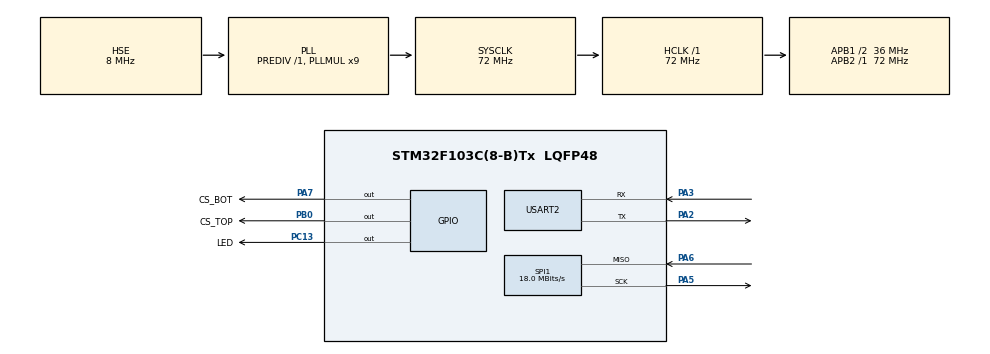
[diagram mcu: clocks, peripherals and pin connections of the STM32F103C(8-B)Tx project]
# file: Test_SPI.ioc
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Dma.Request0=SPI1_RX
Dma.SPI1_RX.0.Direction=DMA_PERIPH_TO_MEMORY
Dma.SPI1_RX.0.Instance=DMA1_Channel2
Dma.SPI1_RX.0.MemDataAlignment=DMA_MDATAALIGN_BYTE
Dma.SPI1_RX.0.MemInc=DMA_MINC_ENABLE
Dma.SPI1_RX.0.Mode=DMA_CIRCULAR
Dma.SPI1_RX.0.PeriphDataAlignment=DMA_PDATAALIGN_BYTE
Dma.SPI1_RX.0.PeriphInc=DMA_PINC_DISABLE
Dma.SPI1_RX.0.Priority=DMA_PRIORITY_LOW
Mcu.Family=STM32F1
Mcu.Name=STM32F103C(8-B)Tx
Mcu.Package=LQFP48
NVIC.DMA1_Channel2_IRQn=true\:0\:0\:false\:false\:true\:false\:true\:true
NVIC.PriorityGroup=NVIC_PRIORITYGROUP_4
NVIC.USART2_IRQn=true\:0\:0\:false\:false\:true\:true\:true\:true
PA13.Mode=Serial_Wire
PA13.Signal=SYS_JTMS-SWDIO
PA14.Mode=Serial_Wire
PA14.Signal=SYS_JTCK-SWCLK
PA2.Mode=Asynchronous
PA2.Signal=USART2_TX
PA3.Mode=Asynchronous
PA3.Signal=USART2_RX
PA5.Mode=RX_Only_Simplex_Unidirect_Master
PA5.Signal=SPI1_SCK
PA6.Mode=RX_Only_Simplex_Unidirect_Master
PA6.Signal=SPI1_MISO
PA7.GPIO_Label=CS_BOT
PA7.PinState=GPIO_PIN_SET
PA7.Signal=GPIO_Output
PB0.GPIO_Label=CS_TOP
PB0.PinState=GPIO_PIN_SET
PB0.Signal=GPIO_Output
PC13-TAMPER-RTC.GPIO_Label=LED
PC13-TAMPER-RTC.Signal=GPIO_Output
PD0-OSC_IN.Mode=HSE-External-Oscillator
PD0-OSC_IN.Signal=RCC_OSC_IN
PD1-OSC_OUT.Mode=HSE-External-Oscillator
PD1-OSC_OUT.Signal=RCC_OSC_OUT
ProjectManager.HeapSize=0x200
ProjectManager.StackSize=0x400
ProjectManager.TargetToolchain=STM32CubeIDE
RCC.AHBFreq_Value=72000000
RCC.APB1CLKDivider=RCC_HCLK_DIV2
RCC.APB1Freq_Value=36000000
RCC.APB1TimFreq_Value=72000000
RCC.APB2Freq_Value=72000000
RCC.APB2TimFreq_Value=72000000
RCC.HCLKFreq_Value=72000000
RCC.PLLMUL=RCC_PLL_MUL9
RCC.PLLSourceVirtual=RCC_PLLSOURCE_HSE
RCC.SYSCLKFreq_VALUE=72000000
RCC.SYSCLKSource=RCC_SYSCLKSOURCE_PLLCLK
RCC.USBFreq_Value=72000000
SPI1.BaudRatePrescaler=SPI_BAUDRATEPRESCALER_4
SPI1.CalculateBaudRate=18.0 MBits/s
SPI1.Direction=SPI_DIRECTION_2LINES_RXONLY
SPI1.Mode=SPI_MODE_MASTER
SPI1.VirtualType=VM_MASTER
USART2.VirtualMode=VM_ASYNC
board=custom

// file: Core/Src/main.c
/* USER CODE BEGIN Header */
/**
  ******************************************************************************
  * @file           : main.c
  * @brief          : Main program body
  ******************************************************************************
  * @attention
  *
  * Copyright (c) 2024 STMicroelectronics.
  * All rights reserved.
  *
  * This software is licensed under terms that can be found in the LICENSE file
  * in the root directory of this software component.
  * If no LICENSE file comes with this software, it is provided AS-IS.
  *
  ******************************************************************************
  */
/* USER CODE END Header */
#include "main.h"

SPI_HandleTypeDef hspi1;
DMA_HandleTypeDef hdma_spi1_rx;

UART_HandleTypeDef huart2;

/* USER CODE BEGIN PV */
#define DATA_SIZE 70
uint8_t Bot_Data[DATA_SIZE] = {0};
uint8_t Top_Data[DATA_SIZE] = {0};
/* USER CODE END PV */

void SystemClock_Config(void);
static void MX_GPIO_Init(void);
static void MX_DMA_Init(void);
static void MX_USART2_UART_Init(void);
static void MX_SPI1_Init(void);

int main(void)
{

  /* MCU Configuration--------------------------------------------------------*/

  /* Reset of all peripherals, Initializes the Flash interface and the Systick. */
  HAL_Init();

  /* Configure the system clock */
  SystemClock_Config();

  /* Initialize all configured peripherals */
  MX_GPIO_Init();
  MX_DMA_Init();
  MX_USART2_UART_Init();
  MX_SPI1_Init();

  /* Infinite loop */
  while (1)
  {

    /* USER CODE BEGIN 3 */

	  HAL_GPIO_TogglePin(LED_GPIO_Port, LED_Pin);

	  HAL_GPIO_WritePin(CS_BOT_GPIO_Port, CS_BOT_Pin, GPIO_PIN_RESET); //start bottom encoder communication
	  HAL_SPI_Receive_DMA(&hspi1, Bot_Data, DATA_SIZE);  //read from encoder
	  HAL_UART_Transmit_IT(&huart2, Bot_Data, DATA_SIZE);//string is displayed in the serial port terminal
	  HAL_GPIO_WritePin(CS_BOT_GPIO_Port, CS_BOT_Pin, GPIO_PIN_SET); //end bottom encoder communication

	  HAL_GPIO_WritePin(CS_TOP_GPIO_Port, CS_TOP_Pin, GPIO_PIN_RESET); //start top encoder communication
	  HAL_SPI_Receive_DMA(&hspi1, Top_Data, DATA_SIZE); //read from encoder
	  HAL_UART_Transmit_IT(&huart2, Top_Data, DATA_SIZE); //string is displayed in the serial port terminal
	  HAL_GPIO_WritePin(CS_TOP_GPIO_Port, CS_TOP_Pin, GPIO_PIN_SET); //end top encoder communication

	  HAL_Delay(1000);
  }
  /* USER CODE END 3 */
}

void SystemClock_Config(void)
{
  RCC_OscInitTypeDef RCC_OscInitStruct = {0};
  RCC_ClkInitTypeDef RCC_ClkInitStruct = {0};

  /** Initializes the RCC Oscillators according to the specified parameters
  * in the RCC_OscInitTypeDef structure.
  */
  RCC_OscInitStruct.OscillatorType = RCC_OSCILLATORTYPE_HSE;
  RCC_OscInitStruct.HSEState = RCC_HSE_ON;
  RCC_OscInitStruct.HSEPredivValue = RCC_HSE_PREDIV_DIV1;
  RCC_OscInitStruct.HSIState = RCC_HSI_ON;
  RCC_OscInitStruct.PLL.PLLState = RCC_PLL_ON;
  RCC_OscInitStruct.PLL.PLLSource = RCC_PLLSOURCE_HSE;
  RCC_OscInitStruct.PLL.PLLMUL = RCC_PLL_MUL9;
  if (HAL_RCC_OscConfig(&RCC_OscInitStruct) != HAL_OK)
  {
    Error_Handler();
  }

  /** Initializes the CPU, AHB and APB buses clocks
  */
  RCC_ClkInitStruct.ClockType = RCC_CLOCKTYPE_HCLK|RCC_CLOCKTYPE_SYSCLK
                              |RCC_CLOCKTYPE_PCLK1|RCC_CLOCKTYPE_PCLK2;
  RCC_ClkInitStruct.SYSCLKSource = RCC_SYSCLKSOURCE_PLLCLK;
  RCC_ClkInitStruct.AHBCLKDivider = RCC_SYSCLK_DIV1;
  RCC_ClkInitStruct.APB1CLKDivider = RCC_HCLK_DIV2;
  RCC_ClkInitStruct.APB2CLKDivider = RCC_HCLK_DIV1;

  if (HAL_RCC_ClockConfig(&RCC_ClkInitStruct, FLASH_LATENCY_2) != HAL_OK)
  {
    Error_Handler();
  }
}

static void MX_SPI1_Init(void)
{

  /* SPI1 parameter configuration*/
  hspi1.Instance = SPI1;
  hspi1.Init.Mode = SPI_MODE_MASTER;
  hspi1.Init.Direction = SPI_DIRECTION_2LINES_RXONLY;
  hspi1.Init.DataSize = SPI_DATASIZE_8BIT;
  hspi1.Init.CLKPolarity = SPI_POLARITY_LOW;
  hspi1.Init.CLKPhase = SPI_PHASE_1EDGE;
  hspi1.Init.NSS = SPI_NSS_SOFT;
  hspi1.Init.BaudRatePrescaler = SPI_BAUDRATEPRESCALER_4;
  hspi1.Init.FirstBit = SPI_FIRSTBIT_MSB;
  hspi1.Init.TIMode = SPI_TIMODE_DISABLE;
  hspi1.Init.CRCCalculation = SPI_CRCCALCULATION_DISABLE;
  hspi1.Init.CRCPolynomial = 10;
  if (HAL_SPI_Init(&hspi1) != HAL_OK)
  {
    Error_Handler();
  }

}

static void MX_USART2_UART_Init(void)
{

  huart2.Instance = USART2;
  huart2.Init.BaudRate = 115200;
  huart2.Init.WordLength = UART_WORDLENGTH_8B;
  huart2.Init.StopBits = UART_STOPBITS_1;
  huart2.Init.Parity = UART_PARITY_NONE;
  huart2.Init.Mode = UART_MODE_TX_RX;
  huart2.Init.HwFlowCtl = UART_HWCONTROL_NONE;
  huart2.Init.OverSampling = UART_OVERSAMPLING_16;
  if (HAL_UART_Init(&huart2) != HAL_OK)
  {
    Error_Handler();
  }

}

static void MX_DMA_Init(void)
{

  /* DMA controller clock enable */
  __HAL_RCC_DMA1_CLK_ENABLE();

  /* DMA interrupt init */
  /* DMA1_Channel2_IRQn interrupt configuration */
  HAL_NVIC_SetPriority(DMA1_Channel2_IRQn, 0, 0);
  HAL_NVIC_EnableIRQ(DMA1_Channel2_IRQn);

}

static void MX_GPIO_Init(void)
{
  GPIO_InitTypeDef GPIO_InitStruct = {0};

  /* GPIO Ports Clock Enable */
  __HAL_RCC_GPIOC_CLK_ENABLE();
  __HAL_RCC_GPIOD_CLK_ENABLE();
  __HAL_RCC_GPIOA_CLK_ENABLE();
  __HAL_RCC_GPIOB_CLK_ENABLE();

  /*Configure GPIO pin Output Level */
  HAL_GPIO_WritePin(LED_GPIO_Port, LED_Pin, GPIO_PIN_RESET);

  /*Configure GPIO pin Output Level */
  HAL_GPIO_WritePin(CS_BOT_GPIO_Port, CS_BOT_Pin, GPIO_PIN_SET);

  /*Configure GPIO pin Output Level */
  HAL_GPIO_WritePin(CS_TOP_GPIO_Port, CS_TOP_Pin, GPIO_PIN_SET);

  /*Configure GPIO pin : LED_Pin */
  GPIO_InitStruct.Pin = LED_Pin;
  GPIO_InitStruct.Mode = GPIO_MODE_OUTPUT_PP;
  GPIO_InitStruct.Pull = GPIO_NOPULL;
  GPIO_InitStruct.Speed = GPIO_SPEED_FREQ_LOW;
  HAL_GPIO_Init(LED_GPIO_Port, &GPIO_InitStruct);

  /*Configure GPIO pin : CS_BOT_Pin */
  GPIO_InitStruct.Pin = CS_BOT_Pin;
  GPIO_InitStruct.Mode = GPIO_MODE_OUTPUT_PP;
  GPIO_InitStruct.Pull = GPIO_NOPULL;
  GPIO_InitStruct.Speed = GPIO_SPEED_FREQ_LOW;
  HAL_GPIO_Init(CS_BOT_GPIO_Port, &GPIO_InitStruct);

  /*Configure GPIO pin : CS_TOP_Pin */
  GPIO_InitStruct.Pin = CS_TOP_Pin;
  GPIO_InitStruct.Mode = GPIO_MODE_OUTPUT_PP;
  GPIO_InitStruct.Pull = GPIO_NOPULL;
  GPIO_InitStruct.Speed = GPIO_SPEED_FREQ_LOW;
  HAL_GPIO_Init(CS_TOP_GPIO_Port, &GPIO_InitStruct);

}

void Error_Handler(void)
{
  __disable_irq();
  while (1)
  {
  }
}
